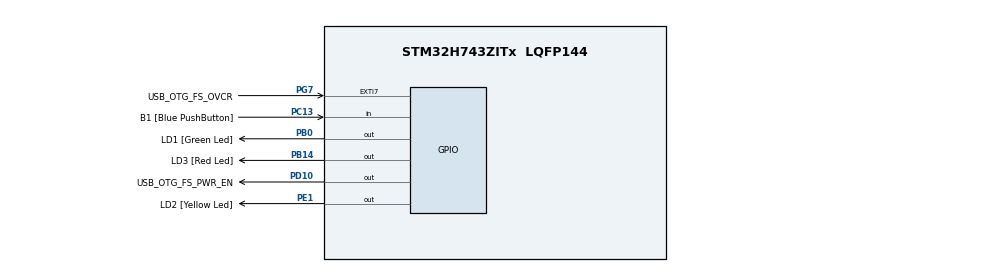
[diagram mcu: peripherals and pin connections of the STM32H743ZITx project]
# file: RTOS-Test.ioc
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FREERTOS.Tasks01=Blink01,24,128,StartBlink01,Default,NULL,Dynamic,NULL,NULL;Blink02,8,128,StartBlink02,Default,NULL,Dynamic,NULL,NULL
Mcu.Family=STM32H7
Mcu.Name=STM32H743ZITx
Mcu.Package=LQFP144
NVIC.PriorityGroup=NVIC_PRIORITYGROUP_4
NVIC.TIM7_IRQn=true\:15\:0\:false\:false\:true\:false\:false\:true\:true
NVIC.TimeBase=TIM7_IRQn
NVIC.TimeBaseIP=TIM7
PA1.Signal=ETH_REF_CLK
PA11.Signal=USB_OTG_FS_DM
PA12.Signal=USB_OTG_FS_DP
PA13\ (JTMS/SWDIO).GPIO_Label=JTMS
PA13\ (JTMS/SWDIO).Signal=DEBUG_JTMS-SWDIO
PA14\ (JTCK/SWCLK).GPIO_Label=JTCK
PA14\ (JTCK/SWCLK).Signal=DEBUG_JTCK-SWCLK
PA2.Signal=ETH_MDIO
PA7.Signal=ETH_CRS_DV
PA8.Signal=USB_OTG_FS_SOF
PA9.Signal=USB_OTG_FS_VBUS
PB0.GPIO_Label=LD1 [Green Led]
PB0.Signal=GPIO_Output
PB13.Signal=ETH_TXD1
PB14.GPIO_Label=LD3 [Red Led]
PB14.Signal=GPIO_Output
PC1.Signal=ETH_MDC
PC13.GPIO_Label=B1 [Blue PushButton]
PC13.Signal=GPIO_Input
PC14-OSC32_IN\ (OSC32_IN).Signal=RCC_OSC32_IN
PC15-OSC32_OUT\ (OSC32_OUT).Signal=RCC_OSC32_OUT
PC4.Signal=ETH_RXD0
PC5.Signal=ETH_RXD1
PD10.GPIO_Label=USB_OTG_FS_PWR_EN
PD10.Signal=GPIO_Output
PD8.GPIO_Label=STLINK_RX
PD8.Signal=USART3_TX
PD9.GPIO_Label=STLINK_TX
PD9.Signal=USART3_RX
PE1.GPIO_Label=LD2 [Yellow Led]
PE1.Signal=GPIO_Output
PG11.Signal=ETH_TX_EN
PG13.Signal=ETH_TXD0
PG7.GPIO_Label=USB_OTG_FS_OVCR
PG7.Signal=GPXTI7
PH0-OSC_IN\ (PH0).Signal=RCC_OSC_IN
PH1-OSC_OUT\ (PH1).Signal=RCC_OSC_OUT
ProjectManager.HeapSize=0x200
ProjectManager.StackSize=0x400
ProjectManager.TargetToolchain=STM32CubeIDE
RCC.ADCFreq_Value=129000000
RCC.APB1Freq_Value=64000000
RCC.APB2Freq_Value=64000000
RCC.APB3Freq_Value=64000000
RCC.APB4Freq_Value=64000000
RCC.CortexFreq_Value=64000000
RCC.HCLKFreq_Value=64000000
RCC.SYSCLKFreq_VALUE=64000000
RCC.USBFreq_Value=129000000
VP_FREERTOS_VS_CMSIS_V2.Mode=CMSIS_V2
VP_SYS_VS_tim7.Mode=TIM7
board=NUCLEO-H743ZI2

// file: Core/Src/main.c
/* USER CODE BEGIN Header */
/**
  ******************************************************************************
  * @file           : main.c
  * @brief          : Main program body
  ******************************************************************************
  * @attention
  *
  * Copyright (c) 2023 STMicroelectronics.
  * All rights reserved.
  *
  * This software is licensed under terms that can be found in the LICENSE file
  * in the root directory of this software component.
  * If no LICENSE file comes with this software, it is provided AS-IS.
  *
  ******************************************************************************
  */
/* USER CODE END Header */
#include "main.h"
#include "cmsis_os.h"

/* USER CODE BEGIN Includes */

#include "stdio.h"

/* USER CODE END Includes */

/* Definitions for Blink01 */
osThreadId_t Blink01Handle;
const osThreadAttr_t Blink01_attributes = {
  .name = "Blink01",
  .stack_size = 128 * 4,
  .priority = (osPriority_t) osPriorityNormal,
};
/* Definitions for Blink02 */
osThreadId_t Blink02Handle;
const osThreadAttr_t Blink02_attributes = {
  .name = "Blink02",
  .stack_size = 128 * 4,
  .priority = (osPriority_t) osPriorityLow,
};

void SystemClock_Config(void);
static void MX_GPIO_Init(void);
void StartBlink01(void *argument);
void StartBlink02(void *argument);

int main(void)
{

  /* MCU Configuration--------------------------------------------------------*/

  /* Reset of all peripherals, Initializes the Flash interface and the Systick. */
  HAL_Init();

  /* Configure the system clock */
  SystemClock_Config();

  /* Initialize all configured peripherals */
  MX_GPIO_Init();

  /* Init scheduler */
  osKernelInitialize();

  /* Create the thread(s) */
  /* creation of Blink01 */
  Blink01Handle = osThreadNew(StartBlink01, NULL, &Blink01_attributes);

  /* creation of Blink02 */
  Blink02Handle = osThreadNew(StartBlink02, NULL, &Blink02_attributes);

  /* Start scheduler */
  osKernelStart();

  /* We should never get here as control is now taken by the scheduler */
  /* Infinite loop */
}

void SystemClock_Config(void)
{
  RCC_OscInitTypeDef RCC_OscInitStruct = {0};
  RCC_ClkInitTypeDef RCC_ClkInitStruct = {0};

  /** Supply configuration update enable
  */
  HAL_PWREx_ConfigSupply(PWR_LDO_SUPPLY);

  /** Configure the main internal regulator output voltage
  */
  __HAL_PWR_VOLTAGESCALING_CONFIG(PWR_REGULATOR_VOLTAGE_SCALE3);

  while(!__HAL_PWR_GET_FLAG(PWR_FLAG_VOSRDY)) {}

  /** Initializes the RCC Oscillators according to the specified parameters
  * in the RCC_OscInitTypeDef structure.
  */
  RCC_OscInitStruct.OscillatorType = RCC_OSCILLATORTYPE_HSI;
  RCC_OscInitStruct.HSIState = RCC_HSI_DIV1;
  RCC_OscInitStruct.HSICalibrationValue = RCC_HSICALIBRATION_DEFAULT;
  RCC_OscInitStruct.PLL.PLLState = RCC_PLL_NONE;
  if (HAL_RCC_OscConfig(&RCC_OscInitStruct) != HAL_OK)
  {
    Error_Handler();
  }

  /** Initializes the CPU, AHB and APB buses clocks
  */
  RCC_ClkInitStruct.ClockType = RCC_CLOCKTYPE_HCLK|RCC_CLOCKTYPE_SYSCLK
                              |RCC_CLOCKTYPE_PCLK1|RCC_CLOCKTYPE_PCLK2
                              |RCC_CLOCKTYPE_D3PCLK1|RCC_CLOCKTYPE_D1PCLK1;
  RCC_ClkInitStruct.SYSCLKSource = RCC_SYSCLKSOURCE_HSI;
  RCC_ClkInitStruct.SYSCLKDivider = RCC_SYSCLK_DIV1;
  RCC_ClkInitStruct.AHBCLKDivider = RCC_HCLK_DIV1;
  RCC_ClkInitStruct.APB3CLKDivider = RCC_APB3_DIV1;
  RCC_ClkInitStruct.APB1CLKDivider = RCC_APB1_DIV1;
  RCC_ClkInitStruct.APB2CLKDivider = RCC_APB2_DIV1;
  RCC_ClkInitStruct.APB4CLKDivider = RCC_APB4_DIV1;

  if (HAL_RCC_ClockConfig(&RCC_ClkInitStruct, FLASH_LATENCY_1) != HAL_OK)
  {
    Error_Handler();
  }
}

static void MX_GPIO_Init(void)
{
  GPIO_InitTypeDef GPIO_InitStruct = {0};

  /* GPIO Ports Clock Enable */
  __HAL_RCC_GPIOC_CLK_ENABLE();
  __HAL_RCC_GPIOH_CLK_ENABLE();
  __HAL_RCC_GPIOA_CLK_ENABLE();
  __HAL_RCC_GPIOB_CLK_ENABLE();
  __HAL_RCC_GPIOD_CLK_ENABLE();
  __HAL_RCC_GPIOG_CLK_ENABLE();
  __HAL_RCC_GPIOE_CLK_ENABLE();

  /*Configure GPIO pin Output Level */
  HAL_GPIO_WritePin(GPIOB, LD1_Pin|LD3_Pin, GPIO_PIN_RESET);

  /*Configure GPIO pin Output Level */
  HAL_GPIO_WritePin(USB_OTG_FS_PWR_EN_GPIO_Port, USB_OTG_FS_PWR_EN_Pin, GPIO_PIN_RESET);

  /*Configure GPIO pin Output Level */
  HAL_GPIO_WritePin(LD2_GPIO_Port, LD2_Pin, GPIO_PIN_RESET);

  /*Configure GPIO pin : B1_Pin */
  GPIO_InitStruct.Pin = B1_Pin;
  GPIO_InitStruct.Mode = GPIO_MODE_INPUT;
  GPIO_InitStruct.Pull = GPIO_NOPULL;
  HAL_GPIO_Init(B1_GPIO_Port, &GPIO_InitStruct);

  /*Configure GPIO pins : PC1 PC4 PC5 */
  GPIO_InitStruct.Pin = GPIO_PIN_1|GPIO_PIN_4|GPIO_PIN_5;
  GPIO_InitStruct.Mode = GPIO_MODE_AF_PP;
  GPIO_InitStruct.Pull = GPIO_NOPULL;
  GPIO_InitStruct.Speed = GPIO_SPEED_FREQ_LOW;
  GPIO_InitStruct.Alternate = GPIO_AF11_ETH;
  HAL_GPIO_Init(GPIOC, &GPIO_InitStruct);

  /*Configure GPIO pins : PA1 PA2 PA7 */
  GPIO_InitStruct.Pin = GPIO_PIN_1|GPIO_PIN_2|GPIO_PIN_7;
  GPIO_InitStruct.Mode = GPIO_MODE_AF_PP;
  GPIO_InitStruct.Pull = GPIO_NOPULL;
  GPIO_InitStruct.Speed = GPIO_SPEED_FREQ_LOW;
  GPIO_InitStruct.Alternate = GPIO_AF11_ETH;
  HAL_GPIO_Init(GPIOA, &GPIO_InitStruct);

  /*Configure GPIO pins : LD1_Pin LD3_Pin */
  GPIO_InitStruct.Pin = LD1_Pin|LD3_Pin;
  GPIO_InitStruct.Mode = GPIO_MODE_OUTPUT_PP;
  GPIO_InitStruct.Pull = GPIO_NOPULL;
  GPIO_InitStruct.Speed = GPIO_SPEED_FREQ_LOW;
  HAL_GPIO_Init(GPIOB, &GPIO_InitStruct);

  /*Configure GPIO pin : PB13 */
  GPIO_InitStruct.Pin = GPIO_PIN_13;
  GPIO_InitStruct.Mode = GPIO_MODE_AF_PP;
  GPIO_InitStruct.Pull = GPIO_NOPULL;
  GPIO_InitStruct.Speed = GPIO_SPEED_FREQ_LOW;
  GPIO_InitStruct.Alternate = GPIO_AF11_ETH;
  HAL_GPIO_Init(GPIOB, &GPIO_InitStruct);

  /*Configure GPIO pins : STLINK_RX_Pin STLINK_TX_Pin */
  GPIO_InitStruct.Pin = STLINK_RX_Pin|STLINK_TX_Pin;
  GPIO_InitStruct.Mode = GPIO_MODE_AF_PP;
  GPIO_InitStruct.Pull = GPIO_NOPULL;
  GPIO_InitStruct.Speed = GPIO_SPEED_FREQ_LOW;
  GPIO_InitStruct.Alternate = GPIO_AF7_USART3;
  HAL_GPIO_Init(GPIOD, &GPIO_InitStruct);

  /*Configure GPIO pin : USB_OTG_FS_PWR_EN_Pin */
  GPIO_InitStruct.Pin = USB_OTG_FS_PWR_EN_Pin;
  GPIO_InitStruct.Mode = GPIO_MODE_OUTPUT_PP;
  GPIO_InitStruct.Pull = GPIO_NOPULL;
  GPIO_InitStruct.Speed = GPIO_SPEED_FREQ_LOW;
  HAL_GPIO_Init(USB_OTG_FS_PWR_EN_GPIO_Port, &GPIO_InitStruct);

  /*Configure GPIO pin : USB_OTG_FS_OVCR_Pin */
  GPIO_InitStruct.Pin = USB_OTG_FS_OVCR_Pin;
  GPIO_InitStruct.Mode = GPIO_MODE_IT_RISING;
  GPIO_InitStruct.Pull = GPIO_NOPULL;
  HAL_GPIO_Init(USB_OTG_FS_OVCR_GPIO_Port, &GPIO_InitStruct);

  /*Configure GPIO pins : PA8 PA11 PA12 */
  GPIO_InitStruct.Pin = GPIO_PIN_8|GPIO_PIN_11|GPIO_PIN_12;
  GPIO_InitStruct.Mode = GPIO_MODE_AF_PP;
  GPIO_InitStruct.Pull = GPIO_NOPULL;
  GPIO_InitStruct.Speed = GPIO_SPEED_FREQ_LOW;
  GPIO_InitStruct.Alternate = GPIO_AF10_OTG1_FS;
  HAL_GPIO_Init(GPIOA, &GPIO_InitStruct);

  /*Configure GPIO pins : PG11 PG13 */
  GPIO_InitStruct.Pin = GPIO_PIN_11|GPIO_PIN_13;
  GPIO_InitStruct.Mode = GPIO_MODE_AF_PP;
  GPIO_InitStruct.Pull = GPIO_NOPULL;
  GPIO_InitStruct.Speed = GPIO_SPEED_FREQ_LOW;
  GPIO_InitStruct.Alternate = GPIO_AF11_ETH;
  HAL_GPIO_Init(GPIOG, &GPIO_InitStruct);

  /*Configure GPIO pin : LD2_Pin */
  GPIO_InitStruct.Pin = LD2_Pin;
  GPIO_InitStruct.Mode = GPIO_MODE_OUTPUT_PP;
  GPIO_InitStruct.Pull = GPIO_NOPULL;
  GPIO_InitStruct.Speed = GPIO_SPEED_FREQ_LOW;
  HAL_GPIO_Init(LD2_GPIO_Port, &GPIO_InitStruct);

}

void StartBlink01(void *argument)
{
  /* USER CODE BEGIN 5 */
  /* Infinite loop */
  for(;;)
  {
	  HAL_GPIO_TogglePin(GPIOB, GPIO_PIN_0);
	  osDelay(400);
  }

  // In case we accidentally exit from task loop
    osThreadTerminate(NULL);
  /* USER CODE END 5 */
}

void StartBlink02(void *argument)
{
  /* USER CODE BEGIN StartBlink02 */
  /* Infinite loop */
  for(;;)
  {
	  HAL_GPIO_TogglePin(GPIOB, GPIO_PIN_14);
	  osDelay(600);
  }

  // In case we accidentally exit from task loop
    osThreadTerminate(NULL);
  /* USER CODE END StartBlink02 */
}

void HAL_TIM_PeriodElapsedCallback(TIM_HandleTypeDef *htim)
{
  if (htim->Instance == TIM7) {
    HAL_IncTick();
  }
}

void Error_Handler(void)
{
  __disable_irq();
  while (1)
  {
  }
}
